VERSION ""

NS_ :

BS_:

BU_: Beifahrertuer Fahrertuer FondtuerRechts Heckklappe KeylessEntry Licht Schiebedach System Wegfahrsperre Wischersteuerung

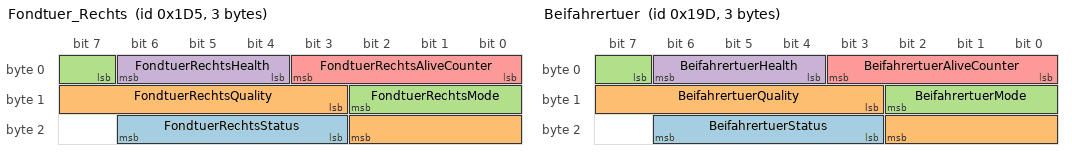
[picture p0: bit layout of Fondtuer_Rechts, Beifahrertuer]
BO_ 469 Fondtuer_Rechts: 3 FondtuerRechts
 SG_ FondtuerRechtsStatus : 19|4@1+ (1,0) [0.0|15.0] "code"  System
 SG_ FondtuerRechtsQuality : 11|8@1+ (0.5,0.0) [0.0|100.0] "%"  System
 SG_ FondtuerRechtsMode : 7|4@1+ (1,0) [0.0|15.0] "code"  System
 SG_ FondtuerRechtsHealth : 4|3@1+ (1,0) [0.0|7.0] "code"  System
 SG_ FondtuerRechtsAliveCounter : 0|4@1+ (1,0) [0.0|15.0] "count"  System

BO_ 413 Beifahrertuer: 3 Beifahrertuer
 SG_ BeifahrertuerStatus : 19|4@1+ (1,0) [0.0|15.0] "code"  System
 SG_ BeifahrertuerQuality : 11|8@1+ (0.5,0.0) [0.0|100.0] "%"  System
 SG_ BeifahrertuerMode : 7|4@1+ (1,0) [0.0|15.0] "code"  System
 SG_ BeifahrertuerHealth : 4|3@1+ (1,0) [0.0|7.0] "code"  System
 SG_ BeifahrertuerAliveCounter : 0|4@1+ (1,0) [0.0|15.0] "count"  System

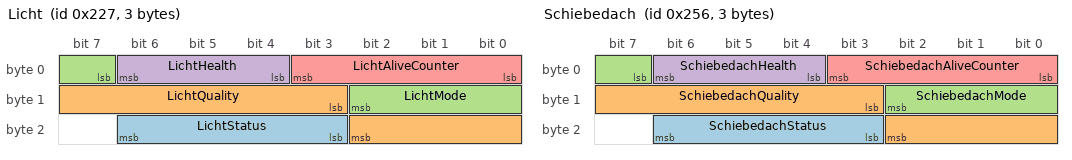
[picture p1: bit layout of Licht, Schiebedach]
BO_ 551 Licht: 3 Licht
 SG_ LichtStatus : 19|4@1+ (1,0) [0.0|15.0] "code"  System
 SG_ LichtQuality : 11|8@1+ (0.5,0.0) [0.0|100.0] "%"  System
 SG_ LichtMode : 7|4@1+ (1,0) [0.0|15.0] "code"  System
 SG_ LichtHealth : 4|3@1+ (1,0) [0.0|7.0] "code"  System
 SG_ LichtAliveCounter : 0|4@1+ (1,0) [0.0|15.0] "count"  System

BO_ 598 Schiebedach: 3 Schiebedach
 SG_ SchiebedachStatus : 19|4@1+ (1,0) [0.0|15.0] "code"  System
 SG_ SchiebedachQuality : 11|8@1+ (0.5,0.0) [0.0|100.0] "%"  System
 SG_ SchiebedachMode : 7|4@1+ (1,0) [0.0|15.0] "code"  System
 SG_ SchiebedachHealth : 4|3@1+ (1,0) [0.0|7.0] "code"  System
 SG_ SchiebedachAliveCounter : 0|4@1+ (1,0) [0.0|15.0] "count"  System

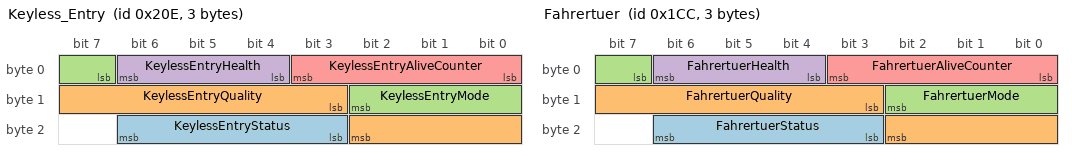
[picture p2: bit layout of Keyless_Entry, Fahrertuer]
BO_ 526 Keyless_Entry: 3 KeylessEntry
 SG_ KeylessEntryStatus : 19|4@1+ (1,0) [0.0|15.0] "code"  System
 SG_ KeylessEntryQuality : 11|8@1+ (0.5,0.0) [0.0|100.0] "%"  System
 SG_ KeylessEntryMode : 7|4@1+ (1,0) [0.0|15.0] "code"  System
 SG_ KeylessEntryHealth : 4|3@1+ (1,0) [0.0|7.0] "code"  System
 SG_ KeylessEntryAliveCounter : 0|4@1+ (1,0) [0.0|15.0] "count"  System

BO_ 460 Fahrertuer: 3 Fahrertuer
 SG_ FahrertuerStatus : 19|4@1+ (1,0) [0.0|15.0] "code"  System
 SG_ FahrertuerQuality : 11|8@1+ (0.5,0.0) [0.0|100.0] "%"  System
 SG_ FahrertuerMode : 7|4@1+ (1,0) [0.0|15.0] "code"  System
 SG_ FahrertuerHealth : 4|3@1+ (1,0) [0.0|7.0] "code"  System
 SG_ FahrertuerAliveCounter : 0|4@1+ (1,0) [0.0|15.0] "count"  System

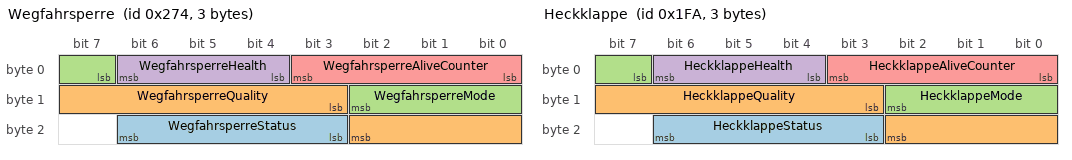
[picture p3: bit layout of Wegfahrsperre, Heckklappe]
BO_ 628 Wegfahrsperre: 3 Wegfahrsperre
 SG_ WegfahrsperreStatus : 19|4@1+ (1,0) [0.0|15.0] "code"  System
 SG_ WegfahrsperreQuality : 11|8@1+ (0.5,0.0) [0.0|100.0] "%"  System
 SG_ WegfahrsperreMode : 7|4@1+ (1,0) [0.0|15.0] "code"  System
 SG_ WegfahrsperreHealth : 4|3@1+ (1,0) [0.0|7.0] "code"  System
 SG_ WegfahrsperreAliveCounter : 0|4@1+ (1,0) [0.0|15.0] "count"  System

BO_ 506 Heckklappe: 3 Heckklappe
 SG_ HeckklappeStatus : 19|4@1+ (1,0) [0.0|15.0] "code"  System
 SG_ HeckklappeQuality : 11|8@1+ (0.5,0.0) [0.0|100.0] "%"  System
 SG_ HeckklappeMode : 7|4@1+ (1,0) [0.0|15.0] "code"  System
 SG_ HeckklappeHealth : 4|3@1+ (1,0) [0.0|7.0] "code"  System
 SG_ HeckklappeAliveCounter : 0|4@1+ (1,0) [0.0|15.0] "count"  System

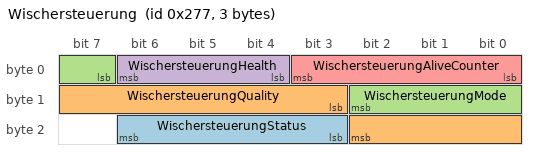
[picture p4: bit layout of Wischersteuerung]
BO_ 631 Wischersteuerung: 3 Wischersteuerung
 SG_ WischersteuerungStatus : 19|4@1+ (1,0) [0.0|15.0] "code"  System
 SG_ WischersteuerungQuality : 11|8@1+ (0.5,0.0) [0.0|100.0] "%"  System
 SG_ WischersteuerungMode : 7|4@1+ (1,0) [0.0|15.0] "code"  System
 SG_ WischersteuerungHealth : 4|3@1+ (1,0) [0.0|7.0] "code"  System
 SG_ WischersteuerungAliveCounter : 0|4@1+ (1,0) [0.0|15.0] "count"  System

CM_ BO_ 469 "CanonicalMessage=fb68cc5e-0000-4b32-a676-30cd1bb2e37d; Network=Karosserie_Komfort_06-S01-CAP-S02; Technology=can_fd";
CM_ SG_ 469 FondtuerRechtsStatus "CanonicalSignal=5e8dca1d-e544-4740-85a7-f822c643b681";
CM_ SG_ 469 FondtuerRechtsQuality "CanonicalSignal=f6c73449-f8db-477f-a864-65aae0512e65";
CM_ SG_ 469 FondtuerRechtsMode "CanonicalSignal=4a771f9c-9604-4a5e-b919-5f6e4f8afa86";
CM_ SG_ 469 FondtuerRechtsHealth "CanonicalSignal=5f6a8bff-a7e1-400e-9545-0ae98266665f";
CM_ SG_ 469 FondtuerRechtsAliveCounter "CanonicalSignal=e3d9efd1-ad8a-4738-9f84-be87df5d20c2";
CM_ BO_ 413 "CanonicalMessage=6e2033ab-263e-4528-8a1a-79933ea6da0b; Network=Karosserie_Komfort_06-S01-CAP-S02; Technology=can_fd";
CM_ SG_ 413 BeifahrertuerStatus "CanonicalSignal=fd3ccc18-7418-4a78-ba0c-f4a72b352720";
CM_ SG_ 413 BeifahrertuerQuality "CanonicalSignal=7a1bafe0-d294-4473-bfd5-c7173df02164";
CM_ SG_ 413 BeifahrertuerMode "CanonicalSignal=295af69d-607f-4fcd-9a4f-b4c6205475ad";
CM_ SG_ 413 BeifahrertuerHealth "CanonicalSignal=5dd41e76-890c-4be2-bfd9-c759c170b0d7";
CM_ SG_ 413 BeifahrertuerAliveCounter "CanonicalSignal=bcb3da61-b47c-4927-af5a-dfcdd649f665";
CM_ BO_ 551 "CanonicalMessage=46ef9d57-a71a-4e8f-903b-ef919dd740f7; Network=Karosserie_Komfort_06-S01-CAP-S02; Technology=can_fd";
CM_ SG_ 551 LichtStatus "CanonicalSignal=8fda21f7-89fd-42a1-aec9-9e74ea53900f";
CM_ SG_ 551 LichtQuality "CanonicalSignal=73aa9108-184e-4031-a10c-329eef474027";
CM_ SG_ 551 LichtMode "CanonicalSignal=4f1bb5a1-dde0-4284-be3b-d20997fb5bd8";
CM_ SG_ 551 LichtHealth "CanonicalSignal=30c61445-5ada-4f59-b623-3e1d97186626";
CM_ SG_ 551 LichtAliveCounter "CanonicalSignal=e5a02489-2c4b-4274-b880-9f4ada999b0b";
CM_ BO_ 598 "CanonicalMessage=fdc72da1-286d-4616-849a-fd5524d4ee69; Network=Karosserie_Komfort_06-S01-CAP-S02; Technology=can_fd";
CM_ SG_ 598 SchiebedachStatus "CanonicalSignal=3fa96d34-ad2f-4293-86f8-50c68b0b9d8d";
CM_ SG_ 598 SchiebedachQuality "CanonicalSignal=a823a87c-2ceb-4964-a63c-12b0bfe51f51";
CM_ SG_ 598 SchiebedachMode "CanonicalSignal=2dca9808-36f4-42e6-bf16-5e7bd6aac394";
CM_ SG_ 598 SchiebedachHealth "CanonicalSignal=c195c8af-b1e2-44fa-8364-aa01f024dc26";
CM_ SG_ 598 SchiebedachAliveCounter "CanonicalSignal=652c8dd9-7962-4506-8e56-e00af4780e1d";
CM_ BO_ 526 "CanonicalMessage=744dbe9b-6b06-4b86-87a0-cebea4c87729; Network=Karosserie_Komfort_06-S01-CAP-S02; Technology=can_fd";
CM_ SG_ 526 KeylessEntryStatus "CanonicalSignal=e1a85f4f-162e-49eb-9312-ddfca3451233";
CM_ SG_ 526 KeylessEntryQuality "CanonicalSignal=574f58b0-fc60-40ee-b6cf-cc6aaab3fcd9";
CM_ SG_ 526 KeylessEntryMode "CanonicalSignal=fe7a33b5-23e5-42e0-bc18-c0a7cdf59b15";
CM_ SG_ 526 KeylessEntryHealth "CanonicalSignal=31386890-8a31-41e1-9914-dd5803af80e9";
CM_ SG_ 526 KeylessEntryAliveCounter "CanonicalSignal=95116512-5865-4146-b968-62d2801d0c92";
CM_ BO_ 460 "CanonicalMessage=3a96f8ee-5262-46a8-9c3d-70e8e02f3a00; Network=Karosserie_Komfort_06-S01-CAP-S02; Technology=can_fd";
CM_ SG_ 460 FahrertuerStatus "CanonicalSignal=d4dfcf9a-9872-4600-aefa-3e3ce22ef47e";
CM_ SG_ 460 FahrertuerQuality "CanonicalSignal=5b217a3a-ffb8-452d-ac66-b54c19329bc3";
CM_ SG_ 460 FahrertuerMode "CanonicalSignal=dcaa228d-4b96-4946-8107-5e9b68965953";
CM_ SG_ 460 FahrertuerHealth "CanonicalSignal=f7b36dd3-87de-48de-b7d9-a8d31387edff";
CM_ SG_ 460 FahrertuerAliveCounter "CanonicalSignal=658b68da-348c-4d32-b3f8-aa3d47a43efb";
CM_ BO_ 628 "CanonicalMessage=d4803056-d21f-4fff-b63e-cf377c8dabb2; Network=Karosserie_Komfort_06-S01-CAP-S02; Technology=can_fd";
CM_ SG_ 628 WegfahrsperreStatus "CanonicalSignal=ebd90670-5482-4f0f-92c4-f7d96bba2fbb";
CM_ SG_ 628 WegfahrsperreQuality "CanonicalSignal=5ef8d399-d4c7-486f-ac49-df3d268fea82";
CM_ SG_ 628 WegfahrsperreMode "CanonicalSignal=cfb7bfe9-4ed6-44d3-abd5-dd21b574cc22";
CM_ SG_ 628 WegfahrsperreHealth "CanonicalSignal=9e4431a4-25c2-46e5-a2ec-fcfab6e269c0";
CM_ SG_ 628 WegfahrsperreAliveCounter "CanonicalSignal=640809d6-9ea6-4242-97eb-e04e8bac6b2e";
CM_ BO_ 506 "CanonicalMessage=de0a6cbc-3469-4efa-8361-2d2598aa1748; Network=Karosserie_Komfort_06-S01-CAP-S02; Technology=can_fd";
CM_ SG_ 506 HeckklappeStatus "CanonicalSignal=0a17671c-4de2-467c-9f3d-485bccaf810f";
CM_ SG_ 506 HeckklappeQuality "CanonicalSignal=c5d7e582-0436-4464-b416-4ef75f4dd43e";
CM_ SG_ 506 HeckklappeMode "CanonicalSignal=896df7d7-5a55-4c76-ab4c-4435dad26fff";
CM_ SG_ 506 HeckklappeHealth "CanonicalSignal=5e31e1cf-eda8-4427-a65e-bcd4d38e429d";
CM_ SG_ 506 HeckklappeAliveCounter "CanonicalSignal=cca98dc7-0723-457f-99ed-6be82ca8cf15";
CM_ BO_ 631 "CanonicalMessage=965e9f72-e3cf-48ce-9b31-024951590fc6; Network=Karosserie_Komfort_06-S01-CAP-S02; Technology=can_fd";
CM_ SG_ 631 WischersteuerungStatus "CanonicalSignal=ce127619-9e4d-4fa6-990c-b149f353c197";
CM_ SG_ 631 WischersteuerungQuality "CanonicalSignal=2f42c7e9-097e-453a-b9c7-134e12a2d2fa";
CM_ SG_ 631 WischersteuerungMode "CanonicalSignal=73cc9ab1-052b-4bc9-8933-adde37f001a9";
CM_ SG_ 631 WischersteuerungHealth "CanonicalSignal=5b3f9d2b-3197-46d1-b8cc-4d9f507b28df";
CM_ SG_ 631 WischersteuerungAliveCounter "CanonicalSignal=5d34aa9a-6932-46e3-8605-e46bad876791";
BA_DEF_ BO_  "VFrameFormat" ENUM  "StandardCAN","ExtendedCAN","StandardCAN_FD","ExtendedCAN_FD";
BA_DEF_DEF_  "VFrameFormat" "0";
BA_ "VFrameFormat" BO_ 469 2;
BA_ "VFrameFormat" BO_ 413 2;
BA_ "VFrameFormat" BO_ 551 2;
BA_ "VFrameFormat" BO_ 598 2;
BA_ "VFrameFormat" BO_ 526 2;
BA_ "VFrameFormat" BO_ 460 2;
BA_ "VFrameFormat" BO_ 628 2;
BA_ "VFrameFormat" BO_ 506 2;
BA_ "VFrameFormat" BO_ 631 2;
